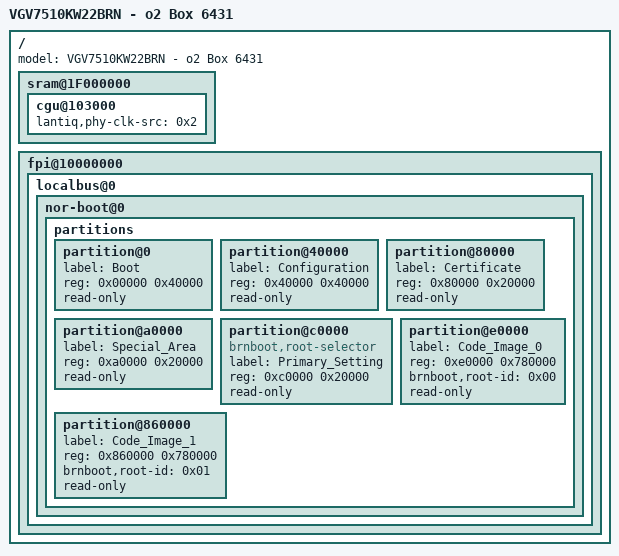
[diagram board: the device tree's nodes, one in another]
/dts-v1/;

#include "VGV7510KW22.dtsi"

/ {
	model = "VGV7510KW22BRN - o2 Box 6431";

	sram@1F000000 {
		cgu@103000 {
			lantiq,phy-clk-src = <0x2>;
		};
	};

	fpi@10000000 {
		localbus@0 {
			nor-boot@0 {
				partitions {
					partition@0 {
						label = "Boot";
						reg = <0x00000 0x40000>;
						read-only;
					};

					partition@40000 {
						label = "Configuration";
						reg = <0x40000 0x40000>;
						read-only;
					};

					partition@80000 {
						label = "Certificate";
						reg = <0x80000 0x20000>;
						read-only;
					};

					partition@a0000 {
						label = "Special_Area";
						reg = <0xa0000 0x20000>;
						read-only;
					};

					partition@c0000 {
						compatible = "brnboot,root-selector";
						label = "Primary_Setting";
						reg = <0xc0000 0x20000>;
						read-only;
					};

					partition@e0000 {
						label = "Code_Image_0";
						reg = <0xe0000 0x780000>;
						brnboot,root-id = <0x00>;
						read-only;
					};

					partition@860000 {
						label = "Code_Image_1";
						reg = <0x860000 0x780000>;
						brnboot,root-id = <0x01>;
						read-only;
					};
				};
			};
		};
	};
};
